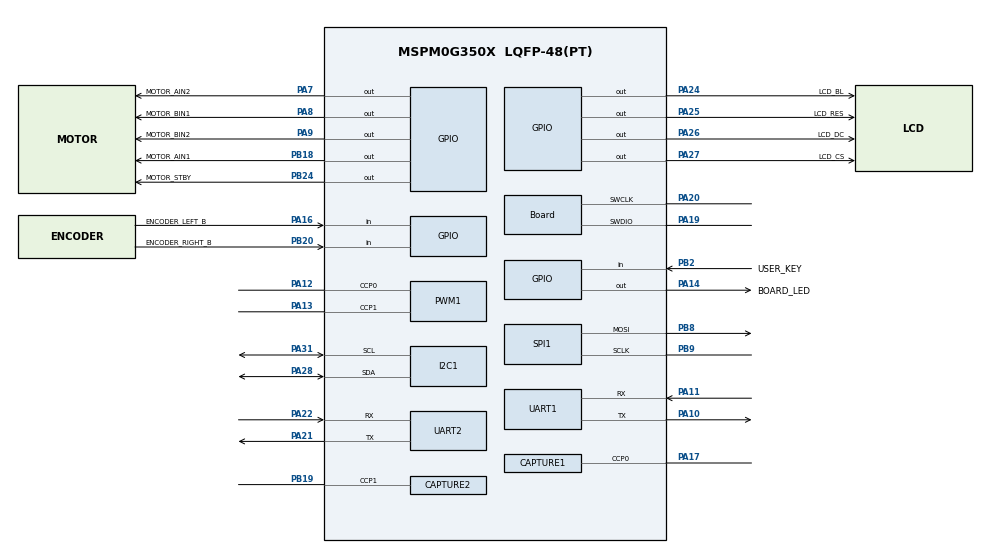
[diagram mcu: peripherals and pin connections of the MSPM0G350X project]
/**
 * @cliArgs --device "MSPM0G350X" --part "Default" --package "LQFP-48(PT)" --product "mspm0_sdk@2.10.00.04"
 * @versions {"tool":"1.26.2+4477"}
 */

/**
 * Import the modules used in this configuration.
 */
const CAPTURE  = scripting.addModule("/ti/driverlib/CAPTURE", {}, false);
const CAPTURE1 = CAPTURE.addInstance();
const CAPTURE2 = CAPTURE.addInstance();
const GPIO     = scripting.addModule("/ti/driverlib/GPIO", {}, false);
const GPIO1    = GPIO.addInstance();
const GPIO2    = GPIO.addInstance();
const I2C      = scripting.addModule("/ti/driverlib/I2C", {}, false);
const I2C1     = I2C.addInstance();
const PWM      = scripting.addModule("/ti/driverlib/PWM", {}, false);
const PWM1     = PWM.addInstance();
const SPI      = scripting.addModule("/ti/driverlib/SPI", {}, false);
const SPI1     = SPI.addInstance();
const SYSCTL   = scripting.addModule("/ti/driverlib/SYSCTL");
const SYSTICK  = scripting.addModule("/ti/driverlib/SYSTICK");
const UART     = scripting.addModule("/ti/driverlib/UART", {}, false);
const UART1    = UART.addInstance();
const UART2    = UART.addInstance();

/**
 * Write custom configuration values to the imported modules.
 */
CAPTURE1.$name                              = "ENCODER_LEFT_CAPTURE";
CAPTURE1.timerClkPrescale                   = 32;
CAPTURE1.timerPeriod                        = "2 ms";
CAPTURE1.captEdgeDetection                  = "EDGE";
CAPTURE1.interrupts                         = ["CC0_DN"];
CAPTURE1.peripheral.$assign                 = "TIMA1";
CAPTURE1.peripheral.ccp0Pin.$assign         = "PA17";
CAPTURE1.ccp0PinConfig.$name                = "ti_driverlib_gpio_GPIOPinGeneric0";
CAPTURE1.ccp0PinConfig.hideOutputInversion  = scripting.forceWrite(false);
CAPTURE1.ccp0PinConfig.onlyInternalResistor = scripting.forceWrite(false);
CAPTURE1.ccp0PinConfig.passedPeripheralType = scripting.forceWrite("Digital");

const Board                       = scripting.addModule("/ti/driverlib/Board", {}, false);
Board.peripheral.$assign          = "DEBUGSS";
Board.peripheral.swclkPin.$assign = "PA20";
Board.peripheral.swdioPin.$assign = "PA19";

CAPTURE2.$name                      = "ENCODER_RIGHT_CAPTURE";
CAPTURE2.timerClkPrescale           = 32;
CAPTURE2.timerPeriod                = "2 ms";
CAPTURE2.captEdgeDetection          = "EDGE";
CAPTURE2.ccIndex                    = 1;
CAPTURE2.interrupts                 = ["CC1_DN"];
CAPTURE2.peripheral.$assign         = "TIMG8";
CAPTURE2.peripheral.ccp1Pin.$assign = "PB19";
CAPTURE2.ccp1PinConfig.$name        = "ti_driverlib_gpio_GPIOPinGeneric1";

GPIO1.$name                          = "GPIO_A";
GPIO1.port                           = "PORTA";
GPIO1.associatedPins.create(12);
GPIO1.associatedPins[0].$name        = "MOTOR_AIN2";
GPIO1.associatedPins[0].assignedPin  = "7";
GPIO1.associatedPins[0].pin.$assign  = "PA7";
GPIO1.associatedPins[1].$name        = "MOTOR_BIN1";
GPIO1.associatedPins[1].assignedPin  = "8";
GPIO1.associatedPins[1].pin.$assign  = "PA8";
GPIO1.associatedPins[2].$name        = "MOTOR_BIN2";
GPIO1.associatedPins[2].assignedPin  = "9";
GPIO1.associatedPins[2].pin.$assign  = "PA9";
GPIO1.associatedPins[3].$name        = "BOARD_LED";
GPIO1.associatedPins[3].assignedPin  = "14";
GPIO1.associatedPins[3].pin.$assign  = "PA14";
GPIO1.associatedPins[4].$name        = "ENCODER_LEFT_B";
GPIO1.associatedPins[4].direction    = "INPUT";
GPIO1.associatedPins[4].assignedPin  = "16";
GPIO1.associatedPins[4].pin.$assign  = "PA16";
GPIO1.associatedPins[5].$name        = "LCD_CS";
GPIO1.associatedPins[5].initialValue = "SET";
GPIO1.associatedPins[5].assignedPin  = "27";
GPIO1.associatedPins[5].pin.$assign  = "PA27";
GPIO1.associatedPins[6].$name        = "LCD_DC";
GPIO1.associatedPins[6].assignedPin  = "26";
GPIO1.associatedPins[6].pin.$assign  = "PA26";
GPIO1.associatedPins[7].$name        = "LCD_RES";
GPIO1.associatedPins[7].initialValue = "SET";
GPIO1.associatedPins[7].assignedPin  = "25";
GPIO1.associatedPins[7].pin.$assign  = "PA25";
GPIO1.associatedPins[8].$name        = "LCD_BL";
GPIO1.associatedPins[8].assignedPin  = "24";
GPIO1.associatedPins[8].pin.$assign  = "PA24";

GPIO2.$name                              = "GPIO_B";
GPIO2.port                               = "PORTB";
GPIO2.associatedPins.create(4);
GPIO2.associatedPins[0].$name            = "MOTOR_AIN1";
GPIO2.associatedPins[0].assignedPin      = "18";
GPIO2.associatedPins[0].pin.$assign      = "PB18";
GPIO2.associatedPins[1].$name            = "MOTOR_STBY";
GPIO2.associatedPins[1].assignedPin      = "24";
GPIO2.associatedPins[1].pin.$assign      = "PB24";
GPIO2.associatedPins[2].$name            = "ENCODER_RIGHT_B";
GPIO2.associatedPins[2].direction        = "INPUT";
GPIO2.associatedPins[2].assignedPin      = "20";
GPIO2.associatedPins[2].pin.$assign      = "PB20";
GPIO2.associatedPins[3].$name            = "USER_KEY";
GPIO2.associatedPins[3].direction        = "INPUT";
GPIO2.associatedPins[3].internalResistor = "PULL_UP";
GPIO2.associatedPins[3].assignedPin      = "2";
GPIO2.associatedPins[3].pin.$assign      = "PB2";

PWM1.$name                              = "MOTOR_PWM";
PWM1.pwmMode                            = "EDGE_ALIGN_UP";
PWM1.peripheral.$assign                 = "TIMG0";
PWM1.peripheral.ccp0Pin.$assign         = "PA12";
PWM1.peripheral.ccp1Pin.$assign         = "PA13";
PWM1.PWM_CHANNEL_0.$name                = "MOTOR_LEFT_PWM";
PWM1.PWM_CHANNEL_1.$name                = "MOTOR_RIGHT_PWM";
PWM1.ccp0PinConfig.$name                = "ti_driverlib_gpio_GPIOPinGeneric2";
PWM1.ccp0PinConfig.direction            = scripting.forceWrite("OUTPUT");
PWM1.ccp0PinConfig.hideOutputInversion  = scripting.forceWrite(false);
PWM1.ccp0PinConfig.onlyInternalResistor = scripting.forceWrite(false);
PWM1.ccp0PinConfig.passedPeripheralType = scripting.forceWrite("Digital");
PWM1.ccp1PinConfig.$name                = "ti_driverlib_gpio_GPIOPinGeneric3";
PWM1.ccp1PinConfig.direction            = scripting.forceWrite("OUTPUT");
PWM1.ccp1PinConfig.hideOutputInversion  = scripting.forceWrite(false);
PWM1.ccp1PinConfig.onlyInternalResistor = scripting.forceWrite(false);
PWM1.ccp1PinConfig.passedPeripheralType = scripting.forceWrite("Digital");

SPI1.$name                              = "LCD_SPI";
SPI1.frameFormat                        = "MOTO3";
SPI1.polarity                           = "1";
SPI1.phase                              = "1";
SPI1.direction                          = "PICO";
SPI1.targetBitRate                      = 4000000;
SPI1.sclkPinConfig.$name                = "ti_driverlib_gpio_GPIOPinGeneric4";
SPI1.sclkPinConfig.direction            = scripting.forceWrite("OUTPUT");
SPI1.sclkPinConfig.onlyInternalResistor = scripting.forceWrite(false);
SPI1.sclkPinConfig.passedPeripheralType = scripting.forceWrite("Digital");
SPI1.mosiPinConfig.$name                = "ti_driverlib_gpio_GPIOPinGeneric5";
SPI1.mosiPinConfig.direction            = scripting.forceWrite("OUTPUT");
SPI1.mosiPinConfig.hideOutputInversion  = scripting.forceWrite(false);
SPI1.mosiPinConfig.onlyInternalResistor = scripting.forceWrite(false);
SPI1.mosiPinConfig.passedPeripheralType = scripting.forceWrite("Digital");
SPI1.peripheral.$assign                 = "SPI1";
SPI1.peripheral.sclkPin.$assign         = "PB9";
SPI1.peripheral.mosiPin.$assign         = "PB8";

I2C1.$name                             = "TRACK_I2C";
I2C1.basicEnableController              = true;
I2C1.basicControllerStandardBusSpeed    = "Fast";
I2C1.peripheral.$assign                 = "I2C0";
I2C1.sdaPinConfig.hideOutputInversion   = scripting.forceWrite(false);
I2C1.sdaPinConfig.onlyInternalResistor  = scripting.forceWrite(false);
I2C1.sdaPinConfig.passedPeripheralType  = scripting.forceWrite("Digital");
I2C1.sdaPinConfig.$name                 = "ti_driverlib_gpio_GPIOPinGeneric12";
I2C1.sclPinConfig.hideOutputInversion   = scripting.forceWrite(false);
I2C1.sclPinConfig.onlyInternalResistor  = scripting.forceWrite(false);
I2C1.sclPinConfig.passedPeripheralType  = scripting.forceWrite("Digital");
I2C1.sclPinConfig.$name                 = "ti_driverlib_gpio_GPIOPinGeneric13";
I2C1.peripheral.sdaPin.$assign          = "PA28";
I2C1.peripheral.sclPin.$assign          = "PA31";

SYSCTL.forceDefaultClkConfig = true;
SYSCTL.clockTreeEn           = true;

SYSTICK.periodEnable    = true;
SYSTICK.systickEnable   = true;
SYSTICK.period          = 32000;
SYSTICK.interruptEnable = true;

UART1.$name                            = "DEBUG_UART";
UART1.targetBaudRate                   = 115200;
UART1.enabledInterrupts                = ["RX"];
UART1.peripheral.$assign               = "UART0";
UART1.peripheral.rxPin.$assign         = "PA11";
UART1.peripheral.txPin.$assign         = "PA10";
UART1.txPinConfig.$name                = "ti_driverlib_gpio_GPIOPinGeneric8";
UART1.txPinConfig.direction            = scripting.forceWrite("OUTPUT");
UART1.txPinConfig.hideOutputInversion  = scripting.forceWrite(false);
UART1.txPinConfig.onlyInternalResistor = scripting.forceWrite(false);
UART1.txPinConfig.passedPeripheralType = scripting.forceWrite("Digital");
UART1.rxPinConfig.$name                = "ti_driverlib_gpio_GPIOPinGeneric9";
UART1.rxPinConfig.hideOutputInversion  = scripting.forceWrite(false);
UART1.rxPinConfig.onlyInternalResistor = scripting.forceWrite(false);
UART1.rxPinConfig.passedPeripheralType = scripting.forceWrite("Digital");

UART2.$name                            = "IMU_UART";
UART2.targetBaudRate                   = 115200;
UART2.enabledInterrupts                = ["RX"];
UART2.peripheral.$assign               = "UART2";
UART2.peripheral.rxPin.$assign         = "PA22";
UART2.peripheral.txPin.$assign         = "PA21";
UART2.txPinConfig.$name                = "ti_driverlib_gpio_GPIOPinGeneric10";
UART2.txPinConfig.direction            = scripting.forceWrite("OUTPUT");
UART2.txPinConfig.hideOutputInversion  = scripting.forceWrite(false);
UART2.txPinConfig.onlyInternalResistor = scripting.forceWrite(false);
UART2.txPinConfig.passedPeripheralType = scripting.forceWrite("Digital");
UART2.rxPinConfig.$name                = "ti_driverlib_gpio_GPIOPinGeneric11";
UART2.rxPinConfig.hideOutputInversion  = scripting.forceWrite(false);
UART2.rxPinConfig.onlyInternalResistor = scripting.forceWrite(false);
UART2.rxPinConfig.passedPeripheralType = scripting.forceWrite("Digital");
